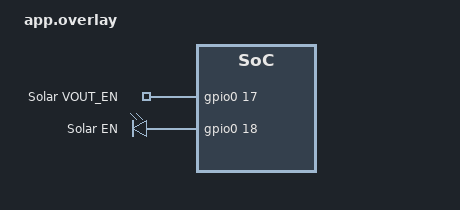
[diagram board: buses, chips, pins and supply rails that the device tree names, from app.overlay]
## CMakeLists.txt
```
#
# Copyright (c) 2021 Nordic Semiconductor
#
# SPDX-License-Identifier: LicenseRef-Nordic-5-Clause
#

cmake_minimum_required(VERSION 3.20)

find_package(Zephyr REQUIRED HINTS $ENV{ZEPHYR_BASE})
project(location)

zephyr_library_sources(
	src/main.c
	src/solar_click.c
)
```

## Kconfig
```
#
# Copyright (c) 2021 Nordic Semiconductor ASA
#
# SPDX-License-Identifier: LicenseRef-Nordic-5-Clause
#

menu "Location sample"

config GOLIOTH_SAMPLE_PSK_ID
	string "Golioth PSK Identity"
	default ""
	help
	  PSK Identity used to authenticate with Golioth (e.g. device-id@project).
	  Set this in a local credentials.conf file, not in tracked source.

config GOLIOTH_SAMPLE_PSK
	string "Golioth PSK"
	default ""
	help
	  Pre-shared key used to authenticate with Golioth.
	  Set this in a local credentials.conf file, not in tracked source.

config GPS_SAMPLE_ANTENNA_ONBOARD
	bool "Enable onboard GNSS antenna power via COEX0"
	default n
	help
	  Send a modem AT command at startup to enable the onboard GNSS
	  antenna/LNA power path on boards that require COEX0 control.

config GPS_SAMPLE_AT_COEX0
	string "AT command used to enable onboard GNSS antenna"
	default "AT\%XCOEX0=1,1,1565,1586"
	help
	  AT command sent when GPS_SAMPLE_ANTENNA_ONBOARD is enabled.

config GPS_SAMPLE_AT_MAGPIO
	string "Optional AT%XMAGPIO command for GNSS RF path"
	default ""
	help
	  Optional board-specific AT command sent before COEX0 to configure
	  MAGPIO/RF routing for GNSS. Leave empty if not required.

config GPS_SAMPLE_AT_MIPIRFFEDEV
	string "Optional AT%XMIPIRFFEDEV command for GNSS RF path"
	default ""
	help
	  Optional board-specific AT command sent before COEX0 to configure
	  MIPI-RFFE device mapping. Leave empty if not required.

config GPS_SAMPLE_AT_MIPIRFFECTRL_INIT
	string "Optional AT%XMIPIRFFECTRL INIT command for GNSS RF path"
	default ""
	help
	  Optional board-specific AT command sent before COEX0 to set MIPI-RFFE
	  control for the INIT state. Leave empty if not required.

config GPS_SAMPLE_AT_MIPIRFFECTRL_ON
	string "Optional AT%XMIPIRFFECTRL ON command for GNSS RF path"
	default ""
	help
	  Optional board-specific AT command sent before COEX0 to set MIPI-RFFE
	  control for the ON state. Leave empty if not required.

config SOLAR_ENERGY_CLICK_MONITOR
	bool "Log Solar Energy 2 Click status GPIOs (BLV, HLV, WUP)"
	default n
	depends on GPIO
	help
	  MikroE Solar Energy 2 Click exposes battery/harvester level indicators and
	  wake on the mikroBUS AN (WUP), INT (HLV), and PWM (BLV) lines. When enabled,
	  the firmware samples those pins on nRF GPIO0 and logs levels periodically.

config SOLAR_ENERGY_CLICK_MONITOR_INTERVAL_SEC
	int "Seconds between Solar Energy Click GPIO log lines"
	depends on SOLAR_ENERGY_CLICK_MONITOR
	range 1 3600
	default 30

config SOLAR_ENERGY_CLICK_GPIO_BLV
	int "nRF GPIO0 pin for BLV (mikroBUS PWM)"
	depends on SOLAR_ENERGY_CLICK_MONITOR
	range 0 31
	default 30 if BOARD_CONEXIO_STRATUS_NRF9160 || BOARD_CONEXIO_STRATUS_NRF9160_NS
	default 3 if BOARD_CONEXIO_STRATUS_PRO_NRF9161 || BOARD_CONEXIO_STRATUS_PRO_NRF9161_NS
	default 30

config SOLAR_ENERGY_CLICK_GPIO_HLV
	int "nRF GPIO0 pin for HLV (mikroBUS INT)"
	depends on SOLAR_ENERGY_CLICK_MONITOR
	range 0 31
	default 29 if BOARD_CONEXIO_STRATUS_NRF9160 || BOARD_CONEXIO_STRATUS_NRF9160_NS
	default 2 if BOARD_CONEXIO_STRATUS_PRO_NRF9161 || BOARD_CONEXIO_STRATUS_PRO_NRF9161_NS
	default 29

config SOLAR_ENERGY_CLICK_GPIO_WUP
	int "nRF GPIO0 pin for WUP (mikroBUS AN)"
	depends on SOLAR_ENERGY_CLICK_MONITOR
	range 0 31
	default 13 if BOARD_CONEXIO_STRATUS_NRF9160 || BOARD_CONEXIO_STRATUS_NRF9160_NS
	default 13 if BOARD_CONEXIO_STRATUS_PRO_NRF9161 || BOARD_CONEXIO_STRATUS_PRO_NRF9161_NS
	default 13

endmenu

menu "Zephyr Kernel"
source "Kconfig.zephyr"
endmenu
```

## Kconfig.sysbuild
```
#
# Copyright (c) 2024 Nordic Semiconductor
#
# SPDX-License-Identifier: LicenseRef-Nordic-5-Clause
#

config WIFI_NRF70
	bool
	default y if BOARD_THINGY91X_NRF9151_NS

choice WIFI_NRF70_OPER_MODES
	bool "Wi-Fi nRF70 operating modes"
	depends on WIFI_NRF70
	default WIFI_NRF70_SCAN_ONLY if BOARD_THINGY91X_NRF9151_NS

config WIFI_NRF70_SCAN_ONLY
	bool "Scan only"

endchoice

source "share/sysbuild/Kconfig"
```

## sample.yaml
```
sample:
  name: location Sample
tests:
  sample.cellular.location:
    sysbuild: true
    build_only: true
    integration_platforms:
      - nrf9151dk/nrf9151/ns
      - nrf9160dk/nrf9160/ns
      - nrf9161dk/nrf9161/ns
      - thingy91/nrf9160/ns
      - thingy91x/nrf9151/ns
    platform_allow:
      - nrf9151dk/nrf9151/ns
      - nrf9160dk/nrf9160/ns
      - nrf9161dk/nrf9161/ns
      - thingy91/nrf9160/ns
      - thingy91x/nrf9151/ns
    tags:
      - ci_build
      - sysbuild
      - ci_samples_cellular
  sample.cellular.location.pgps:
    sysbuild: true
    build_only: true
    extra_args: EXTRA_CONF_FILE=overlay-pgps.conf
    integration_platforms:
      - nrf9151dk/nrf9151/ns
      - nrf9160dk/nrf9160/ns
      - nrf9161dk/nrf9161/ns
    platform_allow:
      - nrf9151dk/nrf9151/ns
      - nrf9160dk/nrf9160/ns
      - nrf9161dk/nrf9161/ns
    tags:
      - ci_build
      - sysbuild
      - ci_samples_cellular
  sample.cellular.location.nrf7002ek_wifi:
    sysbuild: true
    build_only: true
    integration_platforms:
      - nrf9151dk/nrf9151/ns
      - nrf9160dk/nrf9160/ns
      - nrf9161dk/nrf9161/ns
    platform_allow:
      - nrf9151dk/nrf9151/ns
      - nrf9160dk/nrf9160/ns
      - nrf9161dk/nrf9161/ns
    extra_args:
      - SHIELD=nrf7002ek_nrf7000
      - EXTRA_CONF_FILE=overlay-nrf700x-wifi-scan-only.conf
      - SB_CONFIG_WIFI_NRF70=y
      - SB_CONFIG_WIFI_NRF70_SCAN_ONLY=y
    tags:
      - ci_build
      - sysbuild
      - ci_samples_cellular
  sample.cellular.location.nrf7000ek_wifi:
    sysbuild: true
    build_only: true
    integration_platforms:
      - nrf9151dk/nrf9151/ns
      - nrf9160dk/nrf9160/ns
      - nrf9161dk/nrf9161/ns
    platform_allow:
      - nrf9151dk/nrf9151/ns
      - nrf9160dk/nrf9160/ns
      - nrf9161dk/nrf9161/ns
    extra_args:
      - SHIELD=nrf7002ek_nrf7000
      - EXTRA_CONF_FILE=overlay-nrf700x-wifi-scan-only.conf
      - CONFIG_WIFI_NM_WPA_SUPPLICANT=n
      - SB_CONFIG_WIFI_NRF70=y
      - SB_CONFIG_WIFI_NRF70_SCAN_ONLY=y
    tags:
      - ci_build
      - sysbuild
      - ci_samples_cellular
  # Configuration which will be used by the CI positioning integration job to verify PRs
  sample.cellular.location.integration_config_positioning:
    sysbuild: true
    build_only: true
    extra_configs:
      - CONFIG_MODEM_ANTENNA_GNSS_EXTERNAL=y
      - CONFIG_LOG_BUFFER_SIZE=2048
      - CONFIG_NRF_CLOUD_CLIENT_ID_SRC_INTERNAL_UUID=y
    extra_args: location_SNIPPET="nrf91-modem-trace-uart"
    integration_platforms:
      - nrf9151dk/nrf9151/ns
    platform_allow:
      - nrf9151dk/nrf9151/ns
    tags:
      - ci_build
      - sysbuild
      - ci_samples_cellular
```

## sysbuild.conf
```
#
# Sysbuild configuration for Conexio Stratus Pro DFU images.
#

SB_CONFIG_BOOTLOADER_MCUBOOT=y
```

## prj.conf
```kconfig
#
# Copyright (c) 2021 Nordic Semiconductor ASA
#
# SPDX-License-Identifier: LicenseRef-Nordic-5-Clause
#

# General config
CONFIG_FPU=y
CONFIG_NRF_MODEM_LIB=y

# Heap and stacks
CONFIG_MAIN_STACK_SIZE=2048
# Extended memory heap size needed for encoding REST messages to JSON
CONFIG_HEAP_MEM_POOL_SIZE=8192
CONFIG_SYSTEM_WORKQUEUE_STACK_SIZE=1536
# Increase AT monitor heap because %NCELLMEAS notifications can be large
CONFIG_AT_MONITOR_HEAP_SIZE=1024

# Location library
CONFIG_LOCATION=y
# Enable cellular method so GNSS can fall back when sky visibility is poor.
CONFIG_LOCATION_METHOD_CELLULAR=y
# Use nRF Cloud location service for cellular fallback.
CONFIG_LOCATION_SERVICE_NRF_CLOUD=y
CONFIG_LOCATION_SERVICE_EXTERNAL=n
# The location library enforces an overall request timeout; raise it above
# the GNSS method timeout used by the app.
CONFIG_LOCATION_REQUEST_DEFAULT_TIMEOUT=900000
# Require fewer consecutive GNSS fixes (minimum allowed by this SDK is 2).
CONFIG_LOCATION_REQUEST_DEFAULT_GNSS_NUM_CONSECUTIVE_FIXES=2

# Logging (UART on P0.06 TX / P0.05 RX; sensors on i2c1 P0.27 SCL / P0.26 SDA per Stratus V3 schematic)
CONFIG_LOG=y
CONFIG_DK_LIBRARY=y
CONFIG_LOG_MODE_IMMEDIATE=y
# Route printk through LOG so console lines do not interleave with LOG_* from other threads.
CONFIG_LOG_PRINTK=y
CONFIG_UART_CONSOLE=y
CONFIG_LOG_BACKEND_UART=y
CONFIG_USE_SEGGER_RTT=n
CONFIG_RTT_CONSOLE=n
CONFIG_LOG_BACKEND_RTT=n

# Network
CONFIG_NETWORKING=y
# Native IP stack + connection manager (required with overlay-golioth for modem DTLS to Golioth).
CONFIG_NET_NATIVE=y
CONFIG_NET_SOCKETS=y
CONFIG_NET_SOCKETS_OFFLOAD=y

# C library settings from Conexio GNSS sample.
CONFIG_NEWLIB_LIBC=y
CONFIG_NEWLIB_LIBC_FLOAT_PRINTF=y

# LTE link control
CONFIG_LTE_LINK_CONTROL=y
CONFIG_LTE_LC_PSM_MODULE=y
# Enable LTE-M + GPS so the modem GNSS receiver is active (AT%XSYSTEMMODE=1,0,1,0)
CONFIG_LTE_NETWORK_MODE_LTE_M_GPS=y
CONFIG_LTE_NETWORK_MODE_LTE_M_NBIOT_GPS=y
# Disable PSM requests during GNSS validation so GNSS has longer continuous windows.
CONFIG_LTE_PSM_REQ=n
# Disable eDRX requests as well to minimize GNSS interruption from LTE paging cycles.
CONFIG_LTE_EDRX_REQ=n
# Configuration of the onboard GPS antenna power path (board-specific).
CONFIG_GPS_SAMPLE_ANTENNA_ONBOARD=y
CONFIG_GPS_SAMPLE_AT_COEX0="AT\%XCOEX0=1,1,1565,1586"
# Conexio GNSS sample baseline modem antenna setup.
CONFIG_MODEM_ANTENNA=y
CONFIG_MODEM_ANTENNA_GNSS_EXTERNAL=y
CONFIG_MODEM_ANTENNA_AT_MAGPIO="AT\%XMAGPIO=1,0,0,1,1,1574,1577"
CONFIG_MODEM_ANTENNA_AT_COEX0="AT\%XCOEX0=1,1,1565,1586"
# Request periodic TAU of 8 hours
CONFIG_LTE_PSM_REQ_RPTAU="00101000"
# Request PSM active time of 8 seconds.
CONFIG_LTE_PSM_REQ_RAT="00000100"

# AT Host library - Used to send AT commands directy from an UART terminal and to allow
#		    integration with nRF Connect for Desktop LTE Link monitor application.
CONFIG_UART_INTERRUPT_DRIVEN=y
CONFIG_AT_HOST_LIBRARY=n

# Enable nRF Cloud REST + A-GNSS for faster GNSS time-to-first-fix.
# DEFERRED: REST module + runtime allocations exceed heap; disabling for now to validate fallback.
CONFIG_NRF_CLOUD=y
CONFIG_NRF_CLOUD_SEC_TAG=0
CONFIG_NRF_CLOUD_REST=y
CONFIG_NRF_CLOUD_AGNSS=n
CONFIG_MODEM_INFO=y
CONFIG_MODEM_INFO_ADD_NETWORK=y

# Library that maintains the current date time UTC for A-GNSS and P-GPS purposes
CONFIG_DATE_TIME=y

# REST authentication needs JWT (disabled with REST for now).
CONFIG_MODEM_JWT=y

# Keep explicit for parity with Conexio GNSS sample.
CONFIG_BOOTLOADER_MCUBOOT=y

# Onboard sensors on i2c1 (P0.27 SCL / P0.26 SDA): SHT40 + LIS2DH12
CONFIG_SHT4X=y
CONFIG_LIS2DH=y
CONFIG_LIS2DH_TRIGGER_NONE=y
```

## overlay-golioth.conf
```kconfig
#
# Golioth LightDB Stream overlay for nRF9151 (thingy91x)
#
# Apply alongside base prj.conf:
#   west build -b thingy91x_nrf9151_ns -- \
#     -DZEPHYR_EXTRA_MODULES=C:/ncs/v3.2.0/modules/lib/golioth-firmware-sdk \
#     -DEXTRA_CONF_FILE=overlay-golioth.conf
#

# Golioth Firmware SDK (enables CoAP client, DTLS, ZCBOR)
CONFIG_GOLIOTH_FIRMWARE_SDK=y

# LightDB Stream API
CONFIG_GOLIOTH_STREAM=y

# Use PSK authentication (credentials hardcoded in main.c)
CONFIG_GOLIOTH_AUTH_METHOD_PSK=y
# Use a fixed, modem-safe sec tag for TLS credentials used by Golioth.
CONFIG_GOLIOTH_COAP_CLIENT_CREDENTIALS_TAG=42

# nRF91 offloaded networking path
CONFIG_NRF_MODEM_LIB_NET_IF=y
CONFIG_NRF_MODEM_LIB_NET_IF_AUTO_START=y
# Must be off: if the modem attaches LTE before main(), modem_key_mgmt cannot
# write PSK to sec tags ("Not allowed when LTE connection is active").
CONFIG_NRF_MODEM_LIB_NET_IF_AUTO_CONNECT=n
CONFIG_MODEM_KEY_MGMT=y
CONFIG_NET_CONNECTION_MANAGER=y
CONFIG_NET_CONNECTION_MANAGER_MONITOR_STACK_SIZE=1024

# Native mbedTLS (see NET_SOCKETS_TLS_PRIORITY) reads PSK from Zephyr tls_credential_*.
# The nrf_modem TLS backend only mirrors CA/certs into the credential table, not PSK, so
# Golioth DTLS would fail connect() with errno 2 (ENOENT) for tag 42.
CONFIG_TLS_CREDENTIALS_BACKEND_VOLATILE=y

# The current SIM/network reports ESM cause 50 (IPv4 only allowed) when the
# modem asks for dual-stack PDN, so keep the LTE data path IPv4-only.
CONFIG_LTE_LC_PDN_DEFAULTS_OVERRIDE=y
CONFIG_LTE_LC_PDN_DEFAULT_FAM_IPV4=y
CONFIG_NET_NATIVE=y
CONFIG_NET_IPV4=y
# Zephyr IP stack: enable IPv6 node without using IPv6 on the PDN (hello_nrf91_offloaded pattern).
# Fully disabling IPv6 has been linked to offloaded DTLS / getaddrinfo issues on some builds.
CONFIG_NET_IPV6=y
CONFIG_NET_IPV6_NBR_CACHE=n
CONFIG_NET_IPV6_MLD=n
CONFIG_NET_IF_MAX_IPV4_COUNT=1
CONFIG_NET_IF_UNICAST_IPV4_ADDR_COUNT=2

# Prefer Zephyr native TLS/DTLS over modem-offloaded TLS (see Zephyr
# NET_SOCKETS_OFFLOAD_PRIORITY vs NET_SOCKETS_TLS_PRIORITY). Modem offload
# returns ENOTSUP (-109) for some DTLS setsockopt paths Golioth uses.
# Matches golioth-firmware-sdk examples/zephyr/hello/socs/nrf9160_ns.conf.
CONFIG_NET_SOCKETS_TLS_PRIORITY=35
# Allow Golioth DTLS and nRF Cloud REST TLS to coexist during cellular fallback.
CONFIG_NET_SOCKETS_TLS_MAX_CONTEXTS=2

# Golioth DBG helps trace CoAP/DTLS; keep socket layer at INF so
# socket_service_thread DEBUG lines do not splice UART output with printk.
CONFIG_GOLIOTH_LOG_LEVEL_DBG=y
CONFIG_NET_LOG=y
CONFIG_NET_SOCKETS_LOG_LEVEL_INF=y

# Golioth uses eventfd-backed semaphores internally.
CONFIG_ZVFS=y
CONFIG_ZVFS_EVENTFD=y
CONFIG_ZVFS_EVENTFD_MAX=16
CONFIG_ZVFS_OPEN_MAX=25

# Keep TLS settings aligned with Golioth nRF91 reference to avoid invalid
# DTLS option combinations that can surface as connect() EINVAL (-22).
CONFIG_MBEDTLS_KEY_EXCHANGE_PSK_ENABLED=y
CONFIG_MBEDTLS_KEY_EXCHANGE_DHE_PSK_ENABLED=n
CONFIG_MBEDTLS_KEY_EXCHANGE_DHE_RSA_ENABLED=n
CONFIG_MBEDTLS_PK_PARSE_EC_EXTENDED=n
CONFIG_NORDIC_SECURITY_BACKEND=n
CONFIG_MBEDTLS_LEGACY_CRYPTO_C=y
# Match Golioth SDK defaults for NCS+nRF (see port/zephyr/Kconfig GOLIOTH_CIPHERSUITES): GCM first.
# CCM-only was tried earlier for footprint; a fatal server alert (-0x7780 → connect -ECONNABORTED/-113)
# often indicates cipher mismatch — offer GCM and CCM so ClientHello matches cloud negotiation.
CONFIG_GOLIOTH_CIPHERSUITES="TLS_PSK_WITH_AES_128_GCM_SHA256 TLS_PSK_WITH_AES_128_CCM"
CONFIG_MBEDTLS_CIPHER_AES_ENABLED=y
CONFIG_MBEDTLS_CIPHER_CCM_ENABLED=y
CONFIG_MBEDTLS_CIPHER_GCM_ENABLED=y
CONFIG_MBEDTLS_SHA256=y
# mbedtls_ssl_conf_psk fails if key length exceeds this (common Golioth PSK is 32 B).
CONFIG_MBEDTLS_PSK_MAX_LEN=64
# DTLS handshake allocates from mbed heap; too small -> connect() errno 12 (ENOMEM), logged as -12.
# Keep large enough for DTLS but below nRF9160 NS SRAM limit (98304+65536 overflowed RAM ~11 KiB).
CONFIG_MBEDTLS_ENABLE_HEAP=y
CONFIG_MBEDTLS_HEAP_SIZE=86016

# k_malloc users (CoAP, net buffers, etc.) — raise with mbed heap so TLS setup does not starve.
# Note: Reduced for REST/A-GNSS causes Golioth malloc failure; restoring to original 57344 for now.
CONFIG_HEAP_MEM_POOL_SIZE=57344

# Increase system workqueue stack (Golioth runs CoAP retries on it)
CONFIG_SYSTEM_WORKQUEUE_STACK_SIZE=2048

# Leave at Zephyr defaults (-1): Golioth setsockopt runs before mbedtls_ssl_config_defaults()
# and calls mbedtls_ssl_conf_handshake_timeout() on a half-initialized ssl_config, which can
# break the subsequent handshake (connect() errno EINVAL / -22).
CONFIG_GOLIOTH_ZEPHYR_DTLS_HANDSHAKE_TIMEOUT_MIN_MS=-1
CONFIG_GOLIOTH_ZEPHYR_DTLS_HANDSHAKE_TIMEOUT_MAX_MS=-1

# Increase main stack for Golioth client init
CONFIG_MAIN_STACK_SIZE=4096

# Raise max CoAP path length to accommodate paths like "telemetry/snapshot" (18 chars).
# GOLIOTH_COAP_MAX_PATH_LEN is a derived symbol; it is controlled via these two Zephyr CoAP symbols.
CONFIG_COAP_EXTENDED_OPTIONS_LEN=y
CONFIG_COAP_EXTENDED_OPTIONS_LEN_VALUE=32
```

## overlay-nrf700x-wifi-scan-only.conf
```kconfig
#
# Copyright (c) 2022 Nordic Semiconductor ASA
#
# SPDX-License-Identifier: LicenseRef-Nordic-5-Clause
#

# Overlay to use Wi-Fi scanning with one of the following configurations:
# * nRF7002 EK on top of nRF91 Series DK
# * Thingy:91 X

CONFIG_LOCATION_METHOD_WIFI=y
CONFIG_LOCATION_SERVICE_NRF_CLOUD=y

# Align this with CONFIG_NRF_WIFI_SCAN_MAX_BSS_CNT.
# Also see heap allocations.
CONFIG_LOCATION_METHOD_WIFI_SCANNING_RESULTS_MAX_CNT=20

# Actual configs for the Wi-Fi
CONFIG_WIFI=y
CONFIG_WIFI_NRF70=y
CONFIG_WIFI_NRF70_SKIP_LOCAL_ADMIN_MAC=y
# Align this with CONFIG_LOCATION_METHOD_WIFI_SCANNING_RESULTS_MAX_CNT.
# Also see heap allocations.
CONFIG_NRF_WIFI_SCAN_MAX_BSS_CNT=20

# Heap allocations should be changed when CONFIG_LOCATION_METHOD_WIFI_SCANNING_RESULTS_MAX_CNT
# and CONFIG_NRF_WIFI_SCAN_MAX_BSS_CNT (which should be the same value) are changed.
CONFIG_NRF_WIFI_CTRL_HEAP_SIZE=10240
CONFIG_HEAP_MEM_POOL_SIZE=12288
CONFIG_HEAP_MEM_POOL_IGNORE_MIN=y

# Scan only using offload API
CONFIG_WIFI_NM_WPA_SUPPLICANT=n

# For nRF9160 the default is socket interface
CONFIG_NET_DEFAULT_IF_ETHERNET=y
CONFIG_MBEDTLS=n
CONFIG_NORDIC_SECURITY_BACKEND=n

# Networking
CONFIG_NET_L2_ETHERNET=y
CONFIG_NET_NATIVE=y
CONFIG_NET_IPV4=y
CONFIG_NET_DHCPV4=y
CONFIG_NET_STATISTICS=y
CONFIG_NET_STATISTICS_WIFI=y
CONFIG_NET_STATISTICS_USER_API=y
CONFIG_NET_CONTEXT_SYNC_RECV=y

# Memory configurations
CONFIG_NET_BUF_RX_COUNT=1
CONFIG_NET_BUF_TX_COUNT=1
CONFIG_NET_PKT_RX_COUNT=1
CONFIG_NET_PKT_TX_COUNT=1
CONFIG_NET_TX_STACK_SIZE=512
CONFIG_NET_RX_STACK_SIZE=512
CONFIG_NET_TC_TX_COUNT=1
CONFIG_NET_MAX_CONTEXTS=1
CONFIG_NET_MGMT_EVENT_STACK_SIZE=1024
```

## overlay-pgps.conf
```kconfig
#
# Copyright (c) 2021 Nordic Semiconductor ASA
#
# SPDX-License-Identifier: LicenseRef-Nordic-5-Clause
#

# P-GPS overlay configuration

# P-GPS
CONFIG_NRF_CLOUD_REST=y
CONFIG_NRF_CLOUD_PGPS=y
CONFIG_NRF_CLOUD_PGPS_REPLACEMENT_THRESHOLD=4

# Storage for P-GPS
CONFIG_STREAM_FLASH=y
CONFIG_FLASH=y
CONFIG_FLASH_PAGE_LAYOUT=y
CONFIG_FLASH_MAP=y
CONFIG_FCB=y
CONFIG_SETTINGS_FCB=y
CONFIG_MPU_ALLOW_FLASH_WRITE=y

# P-GPS needs more heap
CONFIG_HEAP_MEM_POOL_SIZE=8192

# Download client library stack size needs to be increased with P-GPS
CONFIG_DOWNLOADER_STACK_SIZE=1280
```

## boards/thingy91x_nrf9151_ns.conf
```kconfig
#
# Copyright (c) 2024 Nordic Semiconductor ASA
#
# SPDX-License-Identifier: LicenseRef-Nordic-5-Clause
#

# Configuration file for Thingy:91 X mainly enabling Wi-Fi.
# This file is merged with prj.conf in the application folder, and options
# set here will take precedence if they are present in both files.

CONFIG_LOCATION_METHOD_WIFI=y
CONFIG_LOCATION_SERVICE_NRF_CLOUD=y

# Align this with CONFIG_NRF_WIFI_SCAN_MAX_BSS_CNT.
# Also see comments for CONFIG_HEAP_MEM_POOL_SIZE.
CONFIG_LOCATION_METHOD_WIFI_SCANNING_RESULTS_MAX_CNT=20

# Actual configs for the Wi-Fi
CONFIG_WIFI=y
CONFIG_WIFI_NRF70=y
CONFIG_WIFI_NRF70_SKIP_LOCAL_ADMIN_MAC=y
# Align this with CONFIG_LOCATION_METHOD_WIFI_SCANNING_RESULTS_MAX_CNT.
# Also see comments for CONFIG_HEAP_MEM_POOL_SIZE.
CONFIG_NRF_WIFI_SCAN_MAX_BSS_CNT=20

# Scan only using offload API
CONFIG_WIFI_NM_WPA_SUPPLICANT=n

# For nRF9160 the default is socket interface
CONFIG_NET_DEFAULT_IF_ETHERNET=y
CONFIG_MBEDTLS=n
CONFIG_NORDIC_SECURITY_BACKEND=n

# Networking
CONFIG_NET_L2_ETHERNET=y
CONFIG_NET_NATIVE=y
CONFIG_NET_IPV4=y
CONFIG_NET_DHCPV4=y
CONFIG_NET_STATISTICS=y
CONFIG_NET_STATISTICS_WIFI=y
CONFIG_NET_STATISTICS_USER_API=y
CONFIG_NET_CONTEXT_SYNC_RECV=y

# Memory configurations
CONFIG_NET_BUF_RX_COUNT=1
CONFIG_NET_BUF_TX_COUNT=1
CONFIG_NET_PKT_RX_COUNT=1
CONFIG_NET_PKT_TX_COUNT=1
CONFIG_NET_TX_STACK_SIZE=512
CONFIG_NET_RX_STACK_SIZE=512
CONFIG_NET_TC_TX_COUNT=1
CONFIG_NET_MAX_CONTEXTS=1
CONFIG_NET_MGMT_EVENT_STACK_SIZE=1024

# Heap allocation should be changed when CONFIG_LOCATION_METHOD_WIFI_SCANNING_RESULTS_MAX_CNT
# and CONFIG_NRF_WIFI_SCAN_MAX_BSS_CNT (which should be the same value) are changed.
CONFIG_NRF_WIFI_CTRL_HEAP_SIZE=10240
CONFIG_HEAP_MEM_POOL_SIZE=12288
CONFIG_HEAP_MEM_POOL_IGNORE_MIN=y
```

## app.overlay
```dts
/*
 * Project-specific Solar Energy Click pin mapping for Conexio Stratus Pro nRF9160 NS.
 *
 * Routes per schematics:
 * - INT/VBAT_OK -> P0.16
 * - AN/VOUT_EN  -> P0.17
 * - CS/EN       -> P0.18
 */

/* Override board default solar_int mapping (currently P0.29 in board dtsi). */
&solar_int {
	gpios = <&gpio0 16 (GPIO_PULL_UP | GPIO_ACTIVE_LOW)>;
};

/ {
	solar_ctrls {
		compatible = "gpio-leds";

		solar_vout_en: solar_vout_en {
			gpios = <&gpio0 17 GPIO_ACTIVE_HIGH>;
			label = "Solar VOUT_EN";
		};

		solar_en: solar_en {
			gpios = <&gpio0 18 GPIO_ACTIVE_HIGH>;
			label = "Solar EN";
		};
	};

	aliases {
		solar-vout-en = &solar_vout_en;
		solar-en = &solar_en;
	};
};
```

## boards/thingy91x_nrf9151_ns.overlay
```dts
/* Copyright (c) 2024 Nordic Semiconductor ASA
 *
 * SPDX-License-Identifier: LicenseRef-Nordic-5-Clause
 */

#include <thingy91x_wifi.dtsi>
```

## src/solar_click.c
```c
/*
 * Solar Energy Click GPIO control and VBAT_OK monitor.
 */

#include "solar_click.h"

#include <errno.h>

#include <zephyr/kernel.h>
#include <zephyr/devicetree.h>
#include <zephyr/drivers/gpio.h>
#include <zephyr/sys/printk.h>
#include <zephyr/sys/util.h>

#if DT_HAS_ALIAS(solar_vout_en)
#define SOLAR_VOUT_EN_NODE DT_ALIAS(solar_vout_en)
static const struct gpio_dt_spec solar_vout_en = GPIO_DT_SPEC_GET(SOLAR_VOUT_EN_NODE, gpios);
static bool solar_vout_en_ready;
#endif

#if DT_HAS_ALIAS(solar_en)
#define SOLAR_EN_NODE DT_ALIAS(solar_en)
static const struct gpio_dt_spec solar_en = GPIO_DT_SPEC_GET(SOLAR_EN_NODE, gpios);
static bool solar_en_ready;
#endif

#if DT_HAS_ALIAS(solar_int)
#define SOLAR_INT_NODE DT_ALIAS(solar_int)
static const struct gpio_dt_spec solar_int = GPIO_DT_SPEC_GET(SOLAR_INT_NODE, gpios);
static struct gpio_callback solar_int_cb;
static struct k_work_delayable solar_int_work;
static int solar_int_last_level = -1;
#endif

static solar_click_vbat_ok_handler_t vbat_ok_handler;
static void *vbat_ok_user_data;

int solar_click_register_vbat_ok_handler(solar_click_vbat_ok_handler_t handler, void *user_data)
{
	vbat_ok_handler = handler;
	vbat_ok_user_data = user_data;
	return 0;
}

int solar_click_set_vout_enabled(bool enable)
{
#if DT_HAS_ALIAS(solar_vout_en)
	if (!solar_vout_en_ready) {
		return -ENODEV;
	}

	return gpio_pin_set_dt(&solar_vout_en, enable ? 1 : 0);
#else
	ARG_UNUSED(enable);
	return -ENOTSUP;
#endif
}

int solar_click_set_en(bool enable)
{
#if DT_HAS_ALIAS(solar_en)
	if (!solar_en_ready) {
		return -ENODEV;
	}

	return gpio_pin_set_dt(&solar_en, enable ? 1 : 0);
#else
	ARG_UNUSED(enable);
	return -ENOTSUP;
#endif
}

int solar_click_get_vbat_ok_level(int *level)
{
#if DT_HAS_ALIAS(solar_int)
	if (level == NULL) {
		return -EINVAL;
	}

	*level = gpio_pin_get_dt(&solar_int);
	return *level < 0 ? *level : 0;
#else
	ARG_UNUSED(level);
	return -ENOTSUP;
#endif
}

static int solar_vout_en_init(void)
{
#if DT_HAS_ALIAS(solar_vout_en)
	int err;

	if (!gpio_is_ready_dt(&solar_vout_en)) {
		printk("[solar] VOUT_EN gpio not ready\n");
		return -ENODEV;
	}

	err = gpio_pin_configure_dt(&solar_vout_en, GPIO_OUTPUT_INACTIVE);
	if (err) {
		printk("[solar] VOUT_EN pin config failed: %d\n", err);
		return err;
	}

	solar_vout_en_ready = true;
	printk("[solar] VOUT_EN control enabled on P0.%u (default=0)\n", solar_vout_en.pin);
	return 0;
#else
	printk("[solar] no solar_vout_en alias in devicetree; VOUT_EN control disabled\n");
	return 0;
#endif
}

static int solar_en_init(void)
{
#if DT_HAS_ALIAS(solar_en)
	int err;

	if (!gpio_is_ready_dt(&solar_en)) {
		printk("[solar] EN gpio not ready\n");
		return -ENODEV;
	}

	err = gpio_pin_configure_dt(&solar_en, GPIO_OUTPUT_INACTIVE);
	if (err) {
		printk("[solar] EN pin config failed: %d\n", err);
		return err;
	}

	solar_en_ready = true;
	printk("[solar] EN control enabled on P0.%u (default=0)\n", solar_en.pin);
	return 0;
#else
	printk("[solar] no solar_en alias in devicetree; EN control disabled\n");
	return 0;
#endif
}

#if DT_HAS_ALIAS(solar_int)
static void solar_int_work_handler(struct k_work *work)
{
	ARG_UNUSED(work);

	int level = gpio_pin_get_dt(&solar_int);

	if (level < 0) {
		printk("[solar] failed to read INT pin: %d\n", level);
		return;
	}

	if (solar_int_last_level != level) {
		solar_int_last_level = level;
		printk("[solar] INT level=%d -> %s\n", level,
		       level == 0 ? "low-battery" : "battery-recovered");
		if (vbat_ok_handler != NULL) {
			vbat_ok_handler(level == 0, level, vbat_ok_user_data);
		}
	}
}

static void solar_int_callback(const struct device *dev, struct gpio_callback *cb, uint32_t pins)
{
	ARG_UNUSED(dev);
	ARG_UNUSED(cb);
	ARG_UNUSED(pins);

	/* Debounce/suppress chatter from threshold transitions. */
	k_work_reschedule(&solar_int_work, K_MSEC(25));
}
#endif

static int solar_int_init(void)
{
#if DT_HAS_ALIAS(solar_int)
	int err;

	k_work_init_delayable(&solar_int_work, solar_int_work_handler);

	if (!gpio_is_ready_dt(&solar_int)) {
		printk("[solar] INT gpio not ready\n");
		return -ENODEV;
	}

	err = gpio_pin_configure_dt(&solar_int, GPIO_INPUT);
	if (err) {
		printk("[solar] INT pin config failed: %d\n", err);
		return err;
	}

	err = gpio_pin_interrupt_configure_dt(&solar_int, GPIO_INT_EDGE_BOTH);
	if (err) {
		printk("[solar] INT interrupt config failed: %d\n", err);
		return err;
	}

	gpio_init_callback(&solar_int_cb, solar_int_callback, BIT(solar_int.pin));
	err = gpio_add_callback(solar_int.port, &solar_int_cb);
	if (err) {
		printk("[solar] INT callback add failed: %d\n", err);
		return err;
	}

	k_work_reschedule(&solar_int_work, K_NO_WAIT);
	printk("[solar] INT monitoring enabled on P0.%u\n", solar_int.pin);

	return 0;
#else
	printk("[solar] no solar_int alias in devicetree; INT monitoring disabled\n");
	return 0;
#endif
}

int solar_click_init(void)
{
	int err;
	int first_err = 0;

	err = solar_en_init();
	if (err && first_err == 0) {
		first_err = err;
	}

	err = solar_vout_en_init();
	if (err && first_err == 0) {
		first_err = err;
	}

	/* Safe defaults while energy state is unknown. */
	(void)solar_click_set_en(false);
	(void)solar_click_set_vout_enabled(false);

	err = solar_int_init();
	if (err && first_err == 0) {
		first_err = err;
	}

	if (first_err == 0) {
		printk("[solar] initialization complete (EN=0, VOUT_EN=0)\n");
	}

	return first_err;
}
```

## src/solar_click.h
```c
/*
 * Solar Energy Click integration helpers.
 */

#ifndef SOLAR_CLICK_H_
#define SOLAR_CLICK_H_

#include <stdbool.h>

#ifdef __cplusplus
extern "C" {
#endif

typedef void (*solar_click_vbat_ok_handler_t)(bool low_battery, int level, void *user_data);

int solar_click_init(void);
int solar_click_set_vout_enabled(bool enable);
int solar_click_set_en(bool enable);
int solar_click_get_vbat_ok_level(int *level);
int solar_click_register_vbat_ok_handler(solar_click_vbat_ok_handler_t handler, void *user_data);

#ifdef __cplusplus
}
#endif

#endif /* SOLAR_CLICK_H_ */
```
